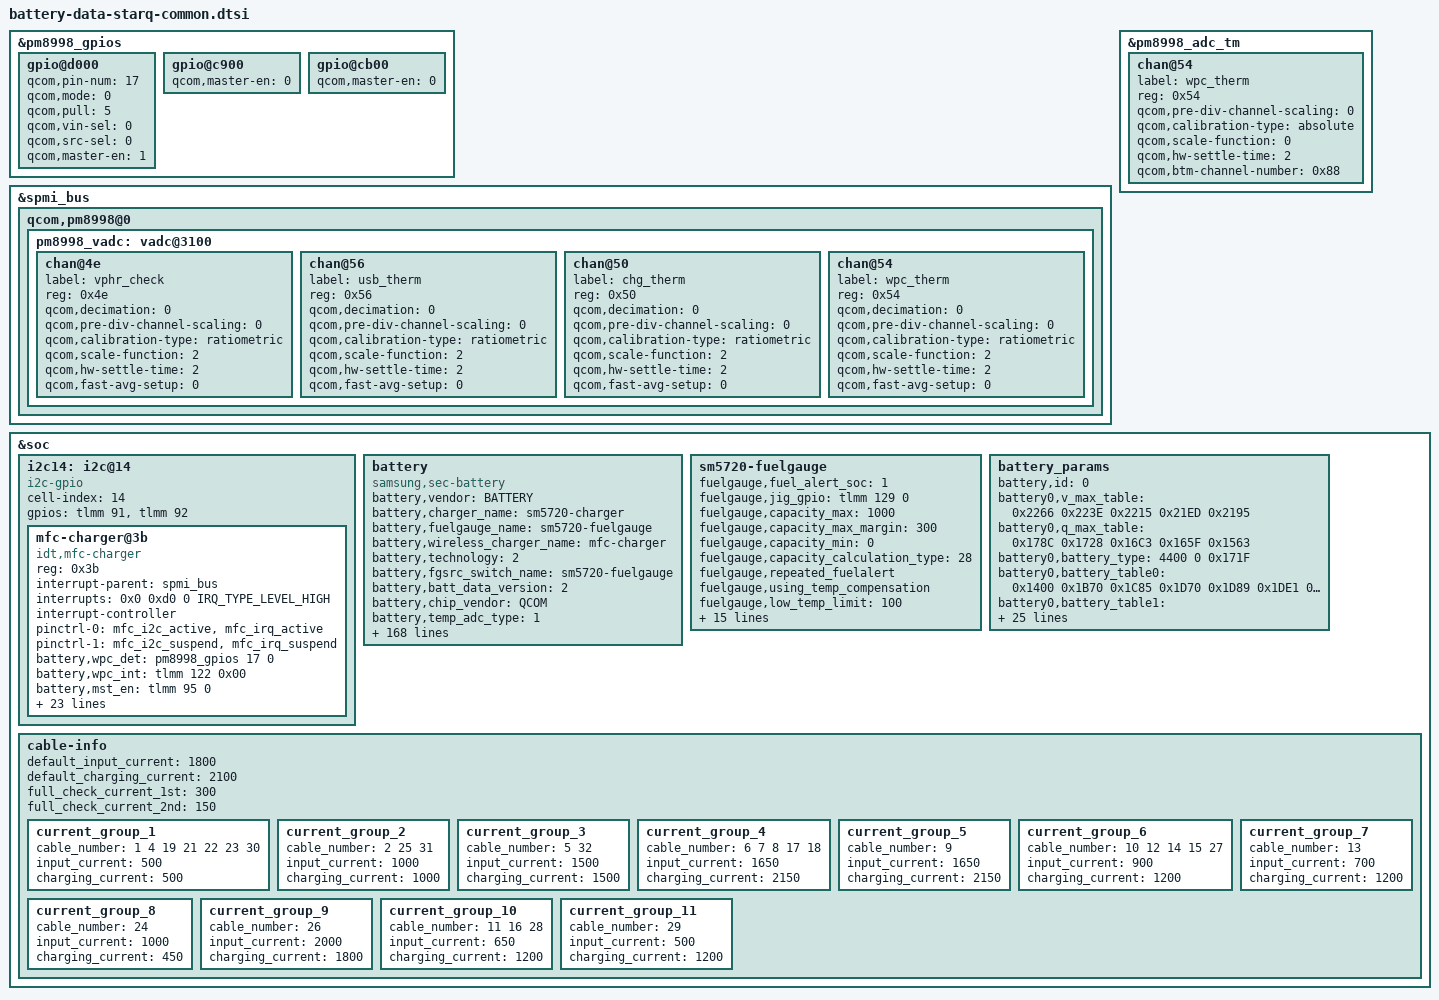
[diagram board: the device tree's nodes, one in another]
/* Copyright (c) 2014, The Linux Foundation. All rights reserved.
 *
 * This program is free software; you can redistribute it and/or modify
 * it under the terms of the GNU General Public License version 2 and
 * only version 2 as published by the Free Software Foundation.
 *
 * This program is distributed in the hope that it will be useful,
 * but WITHOUT ANY WARRANTY; without even the implied warranty of
 * MERCHANTABILITY or FITNESS FOR A PARTICULAR PURPOSE.  See the
 * GNU General Public License for more details.
 */
&pm8998_gpios {
	gpio@d000 { /* PM8998 GPIO 17 for WPC_DET */
		status = "okay";
		qcom,pin-num = <17>;
		qcom,mode = <0>; /* QPNP_PIN_MODE_DIG_IN */
		qcom,pull = <5>; /* QPNP_PIN_PULL_NO */
		qcom,vin-sel = <0>; /* QPNP_PIN_VIN0 */
		qcom,src-sel = <0>; /* QPNP_PIN_SEL_FUNC_CONSTANT */
		qcom,master-en = <1>; /* Enable GPIO */
	};
	gpio@c900 { /* GPIO 10 */
		status = "okay";
		qcom,master-en = <0>;
	};
	gpio@cb00 { /* GPIO 12 */
		status = "okay";
		qcom,master-en = <0>;
	};
};

&spmi_bus {
	qcom,pm8998@0 {
		pm8998_vadc: vadc@3100 {
			chan@4e { /* AMUX_2 */
				label = "vphr_check";
				reg = <0x4e>;
				qcom,decimation = <0>;
				qcom,pre-div-channel-scaling = <0>;
				qcom,calibration-type = "ratiometric";
				qcom,scale-function = <2>;
				qcom,hw-settle-time = <2>;
				qcom,fast-avg-setup = <0>;
			};
			chan@56 { /* PM8998 GPIO 12 */
				label = "usb_therm";
				reg = <0x56>;
				qcom,decimation = <0>;
				qcom,pre-div-channel-scaling = <0>;
				qcom,calibration-type = "ratiometric";
				qcom,scale-function = <2>;
				qcom,hw-settle-time = <2>;
				qcom,fast-avg-setup = <0>;
			};
			chan@50 {
				label = "chg_therm";
				reg = <0x50>;
				qcom,decimation = <0>;
				qcom,pre-div-channel-scaling = <0>;
				qcom,calibration-type = "ratiometric";
				qcom,scale-function = <2>;
				qcom,hw-settle-time = <2>;
				qcom,fast-avg-setup = <0>;
			};
			chan@54 { /* PM8998 GPIO 10 */
				label = "wpc_therm";
				reg = <0x54>;
				qcom,decimation = <0>;
				qcom,pre-div-channel-scaling = <0>;
				qcom,calibration-type = "ratiometric";
				qcom,scale-function = <2>;
				qcom,hw-settle-time = <2>;
				qcom,fast-avg-setup = <0>;
			};
		};
	};
};

&pm8998_adc_tm {
	chan@54 { /* PM8998 GPIO 10 */
		label = "wpc_therm";
		reg = <0x54>;
		qcom,pre-div-channel-scaling = <0>;
		qcom,calibration-type = "absolute";
		qcom,scale-function = <0>;
		qcom,hw-settle-time = <2>;
		qcom,btm-channel-number = <0x88>;
	};
};

&soc {
	i2c14: i2c@14 {
		cell-index = <14>;
		compatible = "i2c-gpio";
		gpios = <&tlmm 91 0 /* MFC_SDA_1P8 */
			&tlmm 92 0 /* MFC_SCL_1P8 */
			>;
		#address-cells = <1>;
		#size-cells = <0>;

		mfc-charger@3b {
			compatible = "idt,mfc-charger";
			reg = <0x3b>;
			status = "okay";

			interrupt-parent = <&spmi_bus>;
			interrupts = <0x0 0xd0 0 IRQ_TYPE_LEVEL_HIGH>;
			interrupt-names = "mfc_wpc_det_irq";
			interrupt-controller;
			pinctrl-names = "default", "mfc_active", "mfc_suspend";
			pinctrl-0 = <&mfc_i2c_active &mfc_irq_active>;
			pinctrl-1 = <&mfc_i2c_suspend &mfc_irq_suspend>;
			battery,wpc_det = <&pm8998_gpios 17 0>; /* WPC_DET */
			battery,wpc_int = <&tlmm 122 0x00>; /* MFC_AP_INT */
			battery,mst_en = <&tlmm 95 0>; /* MST_EN */
			battery,mst_pwr_en = <&expander_gpios 4 0>; /* MST_PWR_EN */

			battery,charger_name = "sm5720-charger";
			battery,fuelgauge_name = "sm5720-fuelgauge";
			battery,wireless_charger_name = "mfc-charger";
			battery,fod_wpc_data = <150 51 142 42 150 27 150 23 165 (-19) 156 12>;
			battery,fod_pma_data = <150 51 142 42 150 27 150 23 165 (-19) 156 12>;
			battery,fod_a4wp_data = <150 51 142 42 150 27 150 23 165 (-19) 156 12>;
			battery,fod_wpc_data_cv = <150 81 142 72 150 57 150 53 165 11 156 42>;
			battery,fod_pma_data_cv = <150 81 142 72 150 57 150 53 165 11 156 42>;
			battery,fod_a4wp_data_cv = <150 81 142 72 150 57 150 53 165 11 156 42>;
			battery,fod_hero_5v_data = <150 11 142 2 150 (-13) 150 (-17) 165 (-59) 156 (-28)>;
			battery,wpc_cc_cv_vout = <5500>;
			battery,wpc_cv_call_vout = <5000>;
			battery,wpc_cc_call_vout = <5000>;
			battery,hv_vout_wa = <0x41>; /* WC vout 10.0V */
			battery,wc_cover_rpp = <0x44>;
		};
	};

	battery {
		status = "okay";
		compatible = "samsung,sec-battery";
		battery,vendor = "BATTERY";
		battery,charger_name = "sm5720-charger";
		battery,fuelgauge_name = "sm5720-fuelgauge";
		battery,wireless_charger_name = "mfc-charger";
		battery,technology = <2>; /* POWER_SUPPLY_TECHNOLOGY_LION */
		battery,fgsrc_switch_name = "sm5720-fuelgauge"; /* Fuelgauge voltage source */

		battery,batt_data_version = <2>;

		battery,chip_vendor = "QCOM";
		battery,temp_adc_type = <1>; /* SEC_BATTERY_ADC_TYPE_AP */

		battery,temp_check_type = <2>; /* SEC_BATTERY_TEMP_CHECK_TEMP */
		battery,chg_temp_check = <1>;
		battery,wpc_temp_check = <1>;

		battery,thermal_source = <2>; /* SEC_BATTERY_THERMAL_SOURCE_ADC */
		battery,usb_thermal_source = <2>; /* SEC_BATTERY_THERMAL_SOURCE_ADC */
		battery,chg_thermal_source = <1>;
		battery,wpc_thermal_source = <1>;
		battery,coil_thermal_source = <1>;

		battery,polling_time = <10 30 30 30 3600>;

		battery,temp_table_adc = <1140 1335 1566 1838 1960
						2037 2182 2479 2996 3600
						4246 4898 5825 6738 7574
						8499 9504 10494 11513 12280
						12957 14654 15073>;
		battery,temp_table_data = <900 850 800 750 700
						650 600 550 500 450
						400 350 300 250 200
						150 100 50 0 (-50)
						(-100) (-150) (-200)>;

		battery,usb_temp_table_adc = <1140 1335 1566 1838 2160
						2337 2476 2806 3355 3992
						4685 5344 6225 7228 7975
						9036 10023 10992 11947 12714
						13337 14654 15073>;
		battery,usb_temp_table_data = <900 850 800 750 700
						650 600 550 500 450
						400 350 300 250 200
						150 100 50 0 (-50)
						(-100) (-150) (-200)>;

		battery,chg_temp_table_adc = <1140 1335 1450 1500 1550
						1600 1683 1933 2369 2894
						3433 4012 4846 5668 6404
						7317 8248 9283 10309 11201
						11928 14654 15073>;
		battery,chg_temp_table_data = <900 850 800 750 700
						650 600 550 500 450
						400 350 300 250 200
						150 100 50 0 (-50)
						(-100) (-150) (-200)>;

		battery,wpc_temp_table_adc = <1140 1335 1566 1838 1960
						2037 2182 2479 2996 3600
						4246 4898 5825 6738 7574
						8499 9504 10494 11513 12280
						12957 14654 15073>;
		battery,wpc_temp_table_data = <900 850 800 750 700
						650 600 550 500 450
						400 350 300 250 200
						150 100 50 0 (-50)
						(-100) (-150) (-200)>;

		battery,wireless_cc_cv = <85>;
		battery,fod_data = <204 8 150 30 130 54 130 54 157 3 157 4>;
		battery,fod_data_cv = <204 38 150 60 130 84 130 84 157 33 157 34>;
		battery,wpc_cc_cv_vout = <5500>;
		battery,wpc_cv_call_vout = <5000>;
		battery,wpc_cc_call_vout = <5000>;
		battery,wpc_det = <&pm8998_gpios 17 0>; /* WPC_DET */
		battery,wpc_en = <&expander_gpios 3 0>; /* WPC_EN */
		battery,hv_vout_wa = <0x41>; /* WC vout 10.0V */
		battery,adc_check_count = <5>;

		battery,cable_check_type = <4>; /* SEC_BATTERY_CABLE_CHECK_PSY */
		battery,cable_source_type = <1>; /* SEC_BATTERY_CABLE_SOURCE_EXTERNAL */
		battery,polling_type = <1>; /* SEC_BATTERY_MONITOR_ALARM */
		battery,monitor_initial_count = <0>;

		battery,battery_check_type = <0>; /* SEC_BATTERY_CHECK_NONE */
		battery,check_count = <0>;
		battery,check_adc_max = <1440>;
		battery,check_adc_min = <0>;

		battery,ovp_uvlo_check_type = <3>; /* SEC_BATTERY_OVP_UVLO_CHGPOLLING */

		battery,temp_check_count = <1>;
		battery,temp_highlimit_threshold_event = <800>;
		battery,temp_highlimit_recovery_event = <750>;
		battery,temp_high_threshold_event = <500>;
		battery,temp_high_recovery_event = <450>;
		battery,temp_low_threshold_event = <0>;
		battery,temp_low_recovery_event = <50>;
		battery,temp_highlimit_threshold_normal = <800>;
		battery,temp_highlimit_recovery_normal = <750>;
		battery,temp_high_threshold_normal = <500>;
		battery,temp_high_recovery_normal = <450>;
		battery,temp_low_threshold_normal = <0>;
		battery,temp_low_recovery_normal = <50>;
		battery,temp_highlimit_threshold_lpm = <800>;
		battery,temp_highlimit_recovery_lpm = <750>;
		battery,temp_high_threshold_lpm = <500>;
		battery,temp_high_recovery_lpm = <450>;
		battery,temp_low_threshold_lpm = <0>;
		battery,temp_low_recovery_lpm = <50>;
		battery,wpc_high_threshold_normal = <450>;
		battery,wpc_high_recovery_normal = <400>;
		battery,wpc_low_threshold_normal = <0>;
		battery,wpc_low_recovery_normal = <50>;
		battery,full_check_type = <7>; /* SEC_BATTERY_FULLCHARGED_CHGPSY */
		battery,full_check_type_2nd = <7>; /* SEC_BATTERY_FULLCHARGED_CHGPSY */
		battery,full_check_count = <1>;
		battery,chg_gpio_full_check = <0>;
		battery,chg_polarity_full_check = <1>;

		battery,chg_high_temp = <460>;
		battery,chg_high_temp_recovery = <440>;
		battery,chg_input_limit_current = <1000>;
		battery,chg_charging_limit_current = <1250>;

		battery,wpc_temp_control_source = <1>; /* TEMP_CONTROL_SOURCE_BAT_THM = WPC_THM */
		battery,wpc_high_temp = <380>;
		battery,wpc_high_temp_recovery = <360>;
		battery,wpc_charging_limit_current = <600>;
		battery,wpc_lcd_on_high_temp = <470>;
		battery,wpc_lcd_on_high_temp_rec = <300>;
		battery,wpc_lcd_on_charging_limit_current = <450>;

		battery,wpc_store_high_temp = <360>;
		battery,wpc_store_high_temp_recovery = <340>;
		battery,wpc_store_charging_limit_current = <400>;
		battery,wpc_store_lcd_on_high_temp = <380>;
		battery,wpc_store_lcd_on_high_temp_rec = <300>;

		battery,sleep_mode_limit_current = <500>;
		battery,wc_full_input_limit_current = <100>;
		battery,wc_cv_current = <820>;
		battery,wc_cv_pack_current = <630>;

		battery,mix_high_temp = <420>;
		battery,mix_high_chg_temp = <500>;
		battery,mix_high_temp_recovery = <390>;

		/* SEC_BATTERY_FULL_CONDITION_NOTIMEFULL |
		   SEC_BATTERY_FULL_CONDITION_VCELL */
		battery,full_condition_type = <9>;
		battery,full_condition_soc = <93>;
		battery,full_condition_vcell = <4250>;

		battery,recharge_check_count = <1>;
		battery,recharge_condition_type = <4>; /* SEC_BATTERY_RECHARGE_CONDITION_VCELL */
		battery,recharge_condition_soc = <98>;
		battery,recharge_condition_vcell = <4280>;

		battery,charging_total_time = <14400>;
		battery,hv_charging_total_time = <10800>;
		battery,normal_charging_total_time = <18000>;
		battery,usb_charging_total_time = <36000>;
		battery,recharging_total_time = <5400>;
		battery,charging_reset_time = <0>;
		qcom,sec-battery-vadc = <&pm8998_vadc>;
		qcom,sec-battery-adc_tm = <&pm8998_adc_tm>;

		battery,chg_float_voltage = <43500>;
		battery,chg_float_voltage_conv = <10>;

		battery,pre_afc_work_delay = <2000>;
		battery,pre_wc_afc_work_delay = <4000>;
		battery,pre_afc_input_current = <1000>;
		battery,pre_wc_afc_input_current = <500>;

		battery,swelling_high_temp_block = <410>;
		battery,swelling_high_temp_recov = <390>;
		battery,swelling_low_temp_block_1st = <150>;
		battery,swelling_low_temp_recov_1st = <200>;
		battery,swelling_low_temp_block_2nd = <50>;
		battery,swelling_low_temp_recov_2nd = <100>;

		battery,swelling_low_temp_current = <700>;	/* 0.3C */
		battery,swelling_low_temp_topoff = <150>;	/* 0.05C */
		battery,swelling_high_temp_current = <1050>;	/* 0.45C */
		battery,swelling_high_temp_topoff = <150>;	/* 0.05C */
		battery,swelling_wc_high_temp_current = <700>;	/* 0.3C */
		battery,swelling_wc_low_temp_current = <700>;	/* 0.3C */

		battery,swelling_drop_float_voltage = <41500>;
		battery,swelling_high_rechg_voltage = <4000>;
		battery,swelling_low_rechg_voltage = <4000>;

		battery,siop_event_check_type = <1>;
		battery,siop_call_cv_current = <330>;
		battery,siop_call_cc_current = <330>;

		battery,siop_input_limit_current = <1200>;
		battery,siop_charging_limit_current = <1000>;
		battery,siop_hv_input_limit_current = <500>;
		battery,siop_hv_charging_limit_current = <1000>;

		battery,siop_wireless_input_limit_current = <600>;
		battery,siop_wireless_charging_limit_current = <700>;
		battery,siop_hv_wireless_input_limit_current = <600>;
		battery,siop_hv_wireless_charging_limit_current = <700>;

		battery,ttf_hv_charge_current = <2150>;
		battery,ttf_hv_wireless_charge_current = <1050>;
		battery,ttf_wireless_charge_current = <900>;

		battery,pd_charging_charge_power = <15000>;
		battery,max_charging_current = <2150>;

		/* cycle, chg_float_voltage, recharge_condition_vcell, full_condition_vcell, full_condition_soc */
		battery,age_data = <0 43500 4280 4250 93
				200 43300 4260 4225 92
				250 43100 4240 4212 91
				300 42900 4220 4187 90
				1000 42400 4170 4137 89>;

		battery,max_input_voltage = <12000>; /* mV */
		battery,max_input_current = <3000>;  /* mA */

		battery,enable_sysovlo_irq;

		battery,standard_curr = <2150>;
		battery,expired_time = <10800>;
		battery,recharging_expired_time = <5400>;

		battery,cisd_cap_high_thr = <4500>; /* 3500 + 1000 */
		battery,cisd_cap_low_thr = <4000>; /* 3500 + 500 */
		battery,cisd_cap_limit = <3850>; /* 3500 + 10% */
		battery,cisd_qh_current_low_thr = <190>;
		battery,cisd_qh_current_high_thr = <210>;
		battery,cisd_qh_vfsoc_thr = <100000>; /* 0.001% */
		battery,cisd_max_voltage_thr = <4400>; /* batttery ovp dettection voltage */
		battery,cisd_alg_index = <7>;
	};

	sm5720-fuelgauge {
		status = "okay";
		fuelgauge,fuel_alert_soc = <1>;
		fuelgauge,jig_gpio = <&tlmm 129 0>; /* IFC_SENSE_INT_AP */
		fuelgauge,capacity_max = <1000>;
		fuelgauge,capacity_max_margin = <300>;
		fuelgauge,capacity_min = <0>;
		fuelgauge,capacity_calculation_type = <28>;
		fuelgauge,repeated_fuelalert;
		fuelgauge,using_temp_compensation;
		fuelgauge,low_temp_limit = <100>;
		fuelgauge,using_hw_vempty;
		fuelgauge,v_empty = <3250>;
		fuelgauge,v_empty_origin = <3400>;
		fuelgauge,sw_v_empty_voltage = <3200>;
		fuelgauge,sw_v_empty_voltage_cisd = <3100>;
		fuelgauge,sw_v_empty_recover_voltage = <3480>;
		fuelgauge,qrtable20 = <0x0d00>;
		fuelgauge,qrtable30 = <0x0a81>;
		fuelgauge,fg_resistor = <2>;
		fuelgauge,jig_low_active = <1>;
		fuelgauge,capacity = <3000>;
		/*fuelgauge,auto_discharge_en;*/
		fuelgauge,discharge_temp_threshold = <600>;
		fuelgauge,discharge_volt_threshold = <4200>;
		fuelgauge,cv_data = <
			2488	829	1809
			2409	832	1796
			2327	837	1769
			2272	840	1743
			2182	846	1721
			2104	850	1690
			2038	854	1670
			1950	859	1640
			1904	861	1622
			1838	865	1594
			1797	867	1576
			1749	870	1560
			1703	873	1531
			1683	873	1525
			1667	875	1515
			1660	875	1512
			1653	876	1509
			1615	878	1502
			1580	880	1483
			1553	881	1463
			1544	882	1458
			1520	883	1451
			1477	886	1424
			1431	888	1409
			1396	891	1383
			1347	894	1361
			1299	896	1332
			1267	898	1315
			1231	902	1288
			1202	904	1263
			1148	906	1243
			1109	909	1213
			1067	911	1185
			1031	914	1156
			1013	915	1140
			975	917	1111
			961	919	1084
			921	921	1064
			892	923	1038
			887	923	1019
			863	925	1004
			833	927	976
			808	929	946
			787	930	918
			780	931	904
			764	932	895
			744	934	864
			730	935	846
			715	936	828
			693	937	800
			681	938	783
			666	940	752
			651	941	735
			640	942	712
			628	945	697
			622	946	679
			618	947	664
			600	950	646
			596	951	627
			589	953	614
			584	953	601
			576	956	572
			577	957	553
			562	958	535
			511	968	506
			505	969	487
			493	971	464
			492	972	435
			484	973	417
			480	975	398
			474	976	380
			470	977	364
			462	977	355
			456	978	336
			452	979	329
			446	981	303
			437	982	282
			429	984	255
			423	985	242
			422	986	229
			414	987	211
			411	988	199
			405	989	191
			397	990	171
			391	991	140
			387	992	126
			384	993	107
			372	995	84
			364	997	54
			356	998	26
			356	998	13
			0	1000	0
			>;
	};

	battery_params {
		battery,id = <0>; /* -1 means auto, detected by F/G */
		battery0,v_max_table = <0x2266 0x223E 0x2215 0x21ED 0x2195>; /* For long life of battery */
		battery0,q_max_table = <0x178C 0x1728 0x16C3 0x165F 0x1563>; /* For long life of battery */
		battery0,battery_type = <4400 0 0x171F>; /* V min max */
		battery0,battery_table0 = <0x1400 0x1B70 0x1C85 0x1D70 0x1D89 0x1DE1 0x1E3A 0x1E91 0x1EDD
						0x1F45 0x1FB7 0x1FED 0x208D 0x20D4 0x223F 0x2400>;
		battery0,battery_table1 = <0x0 0x2F 0x8E 0x145 0x279 0x447 0x748 0xADD 0xCAB 0xDDF 0xFAD
						0x10E0 0x1214 0x1348 0x171F 0x1725>;
		battery0,temp_std = <25>;
		/* en_h, p_de, p_fa, n_de, n_fa, en_l, p_de, p_fa, n_de, n_fa, */
		battery0,temp_cal = <0 6 1 11 (-1) 1 6 1 9 1>;
		/* en_h, p_de, p_fa, n_de, n_fa, en_l, p_de, p_fa, n_de, n_fa, */
		battery0,ext_temp_cal = <0 2 1 2 1 1 2 3 2 3>;
		battery0,temp_volcal = <1 15 1>; /* en, temp, cal */
		battery0,temp_offset = <1 11 1 1 8 (-1)>; /* en_high level offset en_low level offset */
		battery0,cycle_cfg = <7 1 3>; /*high_limit low_limit cntl*/
		battery0,rce_value = <0x04E1 0x03E6 0x01D7>;
		battery0,dtcd_value = <0x1>;
		battery0,rs_value = <0xa4 0x147 0x146 0x3800 0x7a>; /*rs p_mix_factor n_mix_factor max min*/
		battery0,vit_period = <0x0A0A>;
		battery0,mix_value = <0x0103 0x0004>; /*mix_rate init_blank*/
		battery0,misc = <0x00>;
		battery0,topoff_soc = <0 3 300>; /*enable soc current*/
		battery0,curr_offset = <1 0 0 0 0 0 0>; /*en_auto offset*/
		battery0,curr_cal = <0x8f70 0x8080 0x8080 0x8080 0x8080 0x8080>;
		battery0,full_offset = <20 0>; /*margin extra_offset*/
		battery0,volt_cal = <0x8000>;
		battery0,tem_poff = <3400 50 3250 50>;
		battery0,arsm = <1 3 1 0x6>;
		battery0,v_offset_cancel = <0 0 100 10>; /* en_p, en_n, level, mohm */
		battery0,v_alarm = <3100>;
		battery0,data_ver = <2>;
	};

/* sec_battery_cable
 *   0	UNKNOWN,
 *   1	NONE,
 *   2	PREPARE_TA,
 *   3	TA,
 *   4	USB,
 *   5	USB_CDP,
 *   6	9V_TA,
 *   7	9V_ERR,
 *   8	9V_UNKNOWN,
 *   9	12V_TA,
 *  10	WIRELESS,
 *  11	HV_WIRELESS,
 *  12	PMA_WIRELESS,
 *  13	WIRELESS_PACK,
 *  14	WIRELESS_PACK_TA,
 *  15	WIRELESS_STAND,
 *  16	WIRELESS_HV_STAND,
 *  17	QC20,
 *  18	QC30,
 *  19	PDIC,
 *  20	UARTOFF,
 *  21	OTG,
 *  22	LAN_HUB,
 *  23	POWER_SHARING,
 *  24	HMT_CONNECTED,
 *  25	HMT_CHARGE,
 *  26	HV_TA_CHG_LIMIT,
 *  27	WIRELESS_VEHICLE,
 *  28	WIRELESS_HV_VEHICLE,
 *  29	PREPARE_WIRELESS_HV,
 *  30  TIMEOUT,
 *  31  SMART_OTG,
 *  32  SMART_NOTG,
 *  33	CABLE_MAX,
 */
	cable-info {
		default_input_current = <1800>;
		default_charging_current = <2100>;
		full_check_current_1st = <300>;
		full_check_current_2nd = <150>;

		current_group_1 {
			cable_number = <1 4 19 21 22 23 30>;
			input_current = <500>;
			charging_current = <500>;
		};
		current_group_2 {
			cable_number = <2 25 31>;
			input_current = <1000>;
			charging_current = <1000>;
		};
		current_group_3 {
			cable_number = <5 32>;
			input_current = <1500>;
			charging_current = <1500>;
		};
		current_group_4 {
			cable_number = <6 7 8 17 18>;
			input_current = <1650>;
			charging_current = <2150>;
		};
		current_group_5 {
			cable_number = <9>;
			input_current = <1650>;
			charging_current = <2150>;
		};
		current_group_6 {
			cable_number = <10 12 14 15 27>;
			input_current = <900>;
			charging_current = <1200>;
		};
		current_group_7 {
			cable_number = <13>;
			input_current = <700>;
			charging_current = <1200>;
		};
		current_group_8 {
			cable_number = <24>;
			input_current = <1000>;
			charging_current = <450>;
		};
		current_group_9 {
			cable_number = <26>;
			input_current = <2000>;
			charging_current = <1800>;
		};
		current_group_10 {
			cable_number = <11 16 28>;
			input_current = <650>;
			charging_current = <1200>;
		};
		current_group_11 {
			cable_number = <29>;
			input_current = <500>;
			charging_current = <1200>;
		};
	};
};
